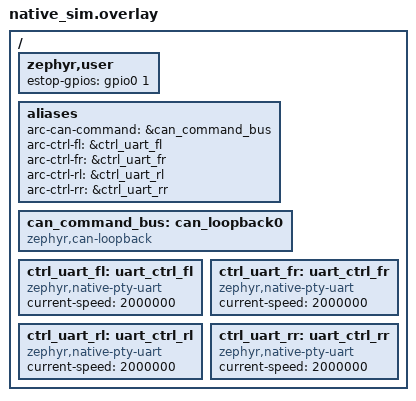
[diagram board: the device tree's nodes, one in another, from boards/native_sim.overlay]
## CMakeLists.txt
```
# Sync MCU firmware (ADR-0017). Build for any target from the repo root:
#   west build -b native_sim     firmware/sync-mcu/app -d firmware/sync-mcu/build/native_sim
#   west build -b nucleo_h723zg  firmware/sync-mcu/app -d firmware/sync-mcu/build/nucleo_h723zg
#   west build -b arc_sync       firmware/sync-mcu/app -d firmware/sync-mcu/build/arc_sync
# or `npx nx build sync-mcu` for all three (ADR-0028).

cmake_minimum_required(VERSION 3.20.0)

# Our own board definitions (boards/arc/arc_sync)
list(APPEND BOARD_ROOT ${CMAKE_CURRENT_LIST_DIR}/..)

find_package(Zephyr REQUIRED HINTS $ENV{ZEPHYR_BASE})
project(arc_sync_mcu)

# Generated from the ICDs (tools/gen-interfaces.sh): sync-link messages
# (systems/icd/sync-link.xml, ADR-0031) and command-bus frames
# (systems/icd/can-command.dbc)
target_include_directories(app PRIVATE generated/arc_mavlink generated/can_command)

target_sources(app PRIVATE
  src/main.c
  src/time_base.c
  src/sensors.c
  src/can_buses.c
  src/can_command_core.c
  generated/can_command/can_command.c
  src/controller_link_core.c
  src/controller_links.c
  src/safety.c
  src/fault_latch.c
  src/estop_input.c
  src/rate_monitor.c
  src/safety_task.c
  src/sync_link.c
)

target_sources_ifdef(CONFIG_ARC_SIM_CAN_BRIDGE app PRIVATE src/sim_can_bridge.c)
target_sources_ifdef(CONFIG_ARC_SIM_ESTOP app PRIVATE src/sim_estop.c)
```

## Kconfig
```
mainmenu "ARC sync MCU"

config ARC_HEARTBEAT_TIMEOUT_MS
	int "Operator heartbeat timeout (ms)"
	default 150
	help
	  Time without an operator heartbeat before the car starts braking
	  (SYS-04: rolls <= 2 m first; ~150 ms is ~1.4 m at 9 m/s; TBC).

config ARC_CAR_MAX_SPEED_MMPS
	int "The car's top speed (mm/s)"
	default 9000
	help
	  The cap for raising the safety envelope's speed limit (SYS-22):
	  SYS-01's 9 m/s. Moves to the car's configuration (ADR-0051).

config ARC_CAR_MAX_ACCEL_MMPS2
	int "The car's maximum acceleration (mm/s^2)"
	default 5000
	help
	  The cap for raising the envelope's acceleration limit (SYS-22).
	  TBD until measured; until then it equals the 5 m/s^2 default
	  (ADR-0052), so the limit can't be raised. Moves to the car's
	  configuration (ADR-0051).

config ARC_CAR_MAX_STEER_MRAD
	int "The car's steering range at the wheels, each side (mrad)"
	default 436
	help
	  About +/-25 degrees (ADR-0019; TBC). The default envelope allows
	  all of it (ADR-0052). Moves to the car's configuration (ADR-0051).

config ARC_COMMAND_TIMEOUT_MS
	int "Orin commands: age after which a command is dropped (ms)"
	default 150
	help
	  With no fresh ARC_DRIVE_COMMAND the output is a zero command (no
	  braking ramp). What the car should do when commands stop while the
	  heartbeat goes on is ICD-sync-link open issue 7; 150 ms follows
	  SYS-04's timeout and is TBC.

config ARC_COMMAND_RATE_HZ
	int "Orin commands: expected arrival rate (Hz)"
	default 500
	help
	  The rate the Orin bridge sends ARC_DRIVE_COMMAND at (ICD-sync-link,
	  TBC). ADR-0011 gives 200-500 Hz for motor commands; 500 Hz is the
	  command-bus budget (budgets/bus-load.csv). Only used to report a
	  stream that is off rate; it never stops the car.

config ARC_COMMAND_RATE_TOLERANCE_PCT
	int "Orin commands: how far off ARC_COMMAND_RATE_HZ is reported (%)"
	default 20
	help
	  TBC, nobody has chosen it. The rate is measured over one second.

config ARC_CAN_BRAKE_CURRENT_MA
	int "Command bus: brake current sent to all four controllers on a stop (mA)"
	default 0
	help
	  TBD: no value in the spec. 0 sends nothing on a stop, and the
	  controllers brake on their own command timeout (ADR-0035), later than
	  SYS-25's 20 ms. Needs the controllers' brake ramp (ADR-0012) settled.

config ARC_CAN_ERPM_PER_MPS
	int "Command bus: electrical rpm per m/s of commanded speed"
	default 0
	help
	  TBD: depends on the wheel diameter, gear ratio and pole pairs, which
	  are still changing (ADR-0026, ADR-0034, ADR-0040). 0 sends 0 A, so the
	  car can't drive until it is set.

config ARC_ESTOP_CUT_MS
	int "Reset: how long the e-stop must be held (ms)"
	default 2400
	help
	  T, the motor-bus cut after an e-stop press (ADR-0034, TBC 2.4 s).
	  A press released sooner doesn't reset a stop (ADR-0039).

config ARC_RESET_CHECK_WINDOW_MS
	int "Reset: how long the power-on checks may take after release (ms)"
	default 3000
	help
	  The controllers restart after the cut and must report again, with
	  no state bits or faults and every wheel stopped, within this time;
	  otherwise the car stays latched (ADR-0039; 3 s set 2026-10-25, TBC).

config ARC_RESET_MAX_STOPS
	int "Reset: stops since power-on that need a restart"
	default 3
	help
	  ADR-0039 item 5 (TBC). Corners reporting the e-stop don't count.

config ARC_WHEEL_STOPPED_ERPM
	int "Reset: the largest |eRPM| that counts as a stopped wheel"
	default 100
	help
	  For the power-on checks' "all wheels stopped" (ADR-0039): an
	  allowance for the speed estimate's noise at standstill
	  (set 2026-10-25, TBC until measured).

config ARC_SIM_ESTOP
	bool "Simulation: the e-stop button over UDP"
	depends on BOARD_NATIVE_SIM && NET_SOCKETS && GPIO_EMUL
	help
	  The emulated e-stop input, set by a simulator over UDP (sim_estop.c).
	  Never on the car.

config ARC_SIM_ESTOP_PORT
	int "Simulation: UDP port for the e-stop button"
	default 52102
	depends on ARC_SIM_ESTOP

config ARC_SIM_CAN_BRIDGE
	bool "Simulation: carry the command bus over UDP"
	depends on BOARD_NATIVE_SIM && NET_SOCKETS
	help
	  The command-bus loopback device, bridged to a simulator over UDP
	  (sim_can_bridge.c). Never on the car.

config ARC_SIM_CAN_PORT_RX
	int "Simulation: UDP port for frames from the simulator"
	default 52100
	depends on ARC_SIM_CAN_BRIDGE

config ARC_SIM_CAN_PORT_TX
	int "Simulation: UDP port for frames to the simulator"
	default 52101
	depends on ARC_SIM_CAN_BRIDGE

config ARC_CONTROLLER_SILENCE_MS
	int "Controller links: silence that stops the car (ms)"
	default 5
	help
	  A motor controller that sends no valid ARC_MOTOR_STATUS for longer
	  than this stops all four corners (SYS-25, ADR-0035; 5 ms is TBC).
	  A host running native_sim in real time with fake controllers can't
	  keep a 5 ms cadence (the scheduler jitters by more); the
	  firmware-in-the-loop run raises it, the unit tests keep the real value.

config ARC_SYNC_LINK_PORT_RX
	int "Sync link: UDP port the sync MCU listens on"
	default 52000
	help
	  ICD-sync-link. The Orin's car backend sends here.

config ARC_SYNC_LINK_PORT_TX
	int "Sync link: UDP port the Orin listens on"
	default 52001
	help
	  ICD-sync-link.

config ARC_SYNC_LINK_PEER
	string "Sync link: the Orin's IPv4 address"
	default "192.168.70.1"
	help
	  The Orin's wired address on the car's internal network
	  (ICD-network, set 2026-10-25, #72). boards/native_sim.conf sets 127.0.0.1 for the
	  firmware and the bridge on one machine.

source "Kconfig.zephyr"
```

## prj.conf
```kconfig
# Common to every target. Target-specific settings live in boards/<board>.conf.
CONFIG_LOG=y
CONFIG_ASSERT=y
```

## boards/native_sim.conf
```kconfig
# native_sim: the sync link runs over the host's own sockets (Zephyr's
# offloaded sockets), so the full stack runs on a laptop (ADR-0028)
CONFIG_NETWORKING=y
CONFIG_NET_IPV4=y
CONFIG_NET_IPV6=n
CONFIG_NET_UDP=y
CONFIG_NET_DRIVERS=y
CONFIG_NET_SOCKETS=y
CONFIG_NET_SOCKETS_OFFLOAD=y
CONFIG_NET_NATIVE_OFFLOADED_SOCKETS=y
CONFIG_ETH_NATIVE_TAP=n
# the bridge runs on this machine too
CONFIG_ARC_SYNC_LINK_PEER="127.0.0.1"
# the controller UARTs (boards/native_sim.overlay), interrupt-driven as on the MCU
CONFIG_SERIAL=y
CONFIG_UART_INTERRUPT_DRIVEN=y
# 1 kHz traffic needs a tick finer than the default 10 ms: a 1 ms sleep would last 10 to 20
CONFIG_SYS_CLOCK_TICKS_PER_SEC=10000
# the command bus: a loopback CAN device, bridged to the simulator over UDP
CONFIG_CAN=y
CONFIG_CAN_LOOPBACK=y
CONFIG_ARC_SIM_CAN_BRIDGE=y
# the e-stop status input: an emulated GPIO the simulator drives over UDP
CONFIG_GPIO=y
CONFIG_ARC_SIM_ESTOP=y
# Placeholders for simulation only; the car's values are TBD (see app/Kconfig):
# 10 A of brake current, and the fake controllers' model (62 mm wheels, 13.5:1, 2 pole pairs)
CONFIG_ARC_CAN_BRAKE_CURRENT_MA=10000
CONFIG_ARC_CAN_ERPM_PER_MPS=8317
```

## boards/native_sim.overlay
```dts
/*
 * native_sim: the four motor-controller UARTs (ICD-controller-telemetry,
 * ADR-0034) as pseudo-terminals. Each prints its /dev/pts path at start-up;
 * tools/sim attaches a fake controller to it. The console stays on stdout.
 */
/ {
	/* the e-stop status input (estop_input.c): an emulated pin, pressed by the
	 * simulator through sim_estop.c; 0 at start-up, released */
	zephyr,user {
		estop-gpios = <&gpio0 1 GPIO_ACTIVE_HIGH>;
	};

	aliases {
		arc-can-command = &can_command_bus;
		arc-ctrl-fl = &ctrl_uart_fl;
		arc-ctrl-fr = &ctrl_uart_fr;
		arc-ctrl-rl = &ctrl_uart_rl;
		arc-ctrl-rr = &ctrl_uart_rr;
	};

	/* the command bus (ADR-0009): a loopback device; sim_can_bridge.c carries it over UDP */
	can_command_bus: can_loopback0 {
		status = "okay";
		compatible = "zephyr,can-loopback";
	};

	ctrl_uart_fl: uart_ctrl_fl {
		status = "okay";
		compatible = "zephyr,native-pty-uart";
		current-speed = <2000000>;
	};

	ctrl_uart_fr: uart_ctrl_fr {
		status = "okay";
		compatible = "zephyr,native-pty-uart";
		current-speed = <2000000>;
	};

	ctrl_uart_rl: uart_ctrl_rl {
		status = "okay";
		compatible = "zephyr,native-pty-uart";
		current-speed = <2000000>;
	};

	ctrl_uart_rr: uart_ctrl_rr {
		status = "okay";
		compatible = "zephyr,native-pty-uart";
		current-speed = <2000000>;
	};
};
```

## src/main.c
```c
/*
 * Sync MCU firmware (ADR-0017): the car's time base, sensors, CAN buses,
 * motor-controller telemetry links, safety envelope and heartbeat watchdog,
 * and the link to the Orin.
 * Architecture: systems/software/architecture.md.
 */

#include <zephyr/kernel.h>
#include <zephyr/logging/log.h>

#include "can_buses.h"
#include "controller_links.h"
#include "safety_task.h"
#ifdef CONFIG_ARC_SIM_CAN_BRIDGE
#include "sim_can_bridge.h"
#endif
#ifdef CONFIG_ARC_SIM_ESTOP
#include "sim_estop.h"
#endif
#include "sensors.h"
#include "sync_link.h"
#include "time_base.h"

LOG_MODULE_REGISTER(main, LOG_LEVEL_INF);

int main(void)
{
	LOG_INF("ARC sync MCU starting on %s", CONFIG_BOARD);

	time_base_init();
	sensors_init();
	safety_task_init(); /* before anything that reads its decision */
	can_buses_init();
	controller_links_init();
	sync_link_init();
#ifdef CONFIG_ARC_SIM_CAN_BRIDGE
	sim_can_bridge_init();
#endif
#ifdef CONFIG_ARC_SIM_ESTOP
	sim_estop_init();
#endif

	while (true) {
		/* everything runs in threads: the controller links, the sync link, the safety task */
		k_sleep(K_SECONDS(1));
	}

	return 0;
}
```

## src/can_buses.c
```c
#include <zephyr/drivers/can.h>
#include <zephyr/kernel.h>
#include <zephyr/logging/log.h>

#include "can_buses.h"

LOG_MODULE_REGISTER(can_buses, LOG_LEVEL_INF);

#if DT_NODE_EXISTS(DT_ALIAS(arc_can_command))

#include "can_command_core.h"
#include "safety_task.h"
#include "time_base.h"

#define COMMAND_BITRATE 1000000 /* ADR-0009: 1 Mbit/s */
#define TX_PERIOD_MS 2          /* 500 Hz (bus-load.csv, TBC) */

static const struct device *const can = DEVICE_DT_GET(DT_ALIAS(arc_can_command));
static const struct cc_config config = {
	.erpm_per_mps = CONFIG_ARC_CAN_ERPM_PER_MPS,
	.brake_current_a = CONFIG_ARC_CAN_BRAKE_CURRENT_MA / 1000.0f,
};

static atomic_t status_count[CC_CORNERS];
static int64_t status_last_ns[CC_CORNERS];

const struct device *can_buses_command_device(void)
{
	return can;
}

uint32_t can_buses_status_count(int corner)
{
	return corner >= 0 && corner < CC_CORNERS ? (uint32_t)atomic_get(&status_count[corner]) : 0;
}

int64_t can_buses_status_last_ns(int corner)
{
	return corner >= 0 && corner < CC_CORNERS ? status_last_ns[corner] : 0;
}

static void on_status(const struct device *dev, struct can_frame *frame, void *user_data)
{
	ARG_UNUSED(dev);
	ARG_UNUSED(user_data);

	int corner = cc_status_1_corner(frame->id);

	if (corner >= 0) {
		status_last_ns[corner] = time_base_now_ns();
		atomic_inc(&status_count[corner]);
	}
}

static void tx_thread(void *a, void *b, void *c)
{
	ARG_UNUSED(a);
	ARG_UNUSED(b);
	ARG_UNUSED(c);

	enum cc_kind last_kind = (enum cc_kind)-1;
	uint32_t errors = 0;

	while (true) {
		struct safety_output decision = safety_task_output();
		struct cc_plan plan = cc_make_plan(&config, &decision);

		if (plan.kind != last_kind) {
			LOG_INF("command bus: sending %s", cc_kind_name(plan.kind));
			if (plan.kind == CC_NONE) {
				LOG_ERR("braking, but ARC_CAN_BRAKE_CURRENT_MA is not set: the "
					"controllers brake on their own timeout (150 ms), not "
					"within SYS-25's 20 ms");
			}
			last_kind = plan.kind;
		}
		if (plan.kind != CC_NONE) {
			for (int i = 0; i < CC_CORNERS; i++) {
				struct can_frame f = {.id = plan.frame[i].id, .flags = CAN_FRAME_IDE,
						      .dlc = plan.frame[i].len};

				memcpy(f.data, plan.frame[i].data, plan.frame[i].len);
				int err = can_send(can, &f, K_NO_WAIT, NULL, NULL);

				if (err && (errors++ % 1000) == 0) {
					LOG_WRN("command bus: send failed (%d), %u so far", err,
						errors);
				}
			}
		}
		k_sleep(K_MSEC(TX_PERIOD_MS));
	}
}

K_THREAD_STACK_DEFINE(can_tx_stack, 2048);
static struct k_thread tx_data;

int can_buses_init(void)
{
	if (!device_is_ready(can)) {
		LOG_ERR("command bus device not ready");
		return -ENODEV;
	}
	int err = can_set_bitrate(can, COMMAND_BITRATE);

	if (err && err != -ENOTSUP) {
		LOG_ERR("command bus bitrate: %d", err);
		return err;
	}
#if DT_NODE_HAS_COMPAT(DT_ALIAS(arc_can_command), zephyr_can_loopback)
	/* the loopback device hands a sent frame to the receive filters only in this mode:
	 * that is how sim_can_bridge.c sees what the firmware sends */
	err = can_set_mode(can, CAN_MODE_LOOPBACK);
	if (err) {
		LOG_ERR("command bus mode: %d", err);
		return err;
	}
#endif
	err = can_start(can);
	if (err) {
		LOG_ERR("command bus start: %d", err);
		return err;
	}
	for (int i = 0; i < CC_CORNERS; i++) {
		struct can_filter filter = {.id = cc_status_1_id(i), .mask = CAN_EXT_ID_MASK,
					    .flags = CAN_FILTER_IDE};

		if (can_add_rx_filter(can, on_status, NULL, &filter) < 0) {
			LOG_ERR("command bus: no filter for STATUS_1 of corner %d", i);
			return -ENOSPC;
		}
	}
	k_thread_create(&tx_data, can_tx_stack, K_THREAD_STACK_SIZEOF(can_tx_stack), tx_thread, NULL, NULL,
			NULL, K_PRIO_PREEMPT(4), 0, K_NO_WAIT);
	k_thread_name_set(&tx_data, "can_tx");
	LOG_INF("command bus up: %d bit/s, every %d ms to the four controllers", COMMAND_BITRATE,
		TX_PERIOD_MS);
	return 0;
}

#else

const struct device *can_buses_command_device(void)
{
	return NULL;
}

uint32_t can_buses_status_count(int corner)
{
	ARG_UNUSED(corner);
	return 0;
}

int64_t can_buses_status_last_ns(int corner)
{
	ARG_UNUSED(corner);
	return 0;
}

int can_buses_init(void)
{
	LOG_INF("not implemented yet");
	return 0;
}

#endif
```

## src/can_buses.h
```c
/*
 * The CAN buses: classic command bus to the four motor controllers
 * (ADR-0009) and the CAN-FD steering bus to the moteus-c1 (ADR-0019).
 * Command frame layouts come from can-command.dbc.
 *
 * The command bus sends every 2 ms, to all four controllers: the safety
 * decision as frames (can_command_core), never silent, so the controllers'
 * own command timeout trips only on real loss (ADR-0035). It receives
 * STATUS_1 from each controller. The steering bus is a stub.
 *
 * Only native_sim has the command-bus device so far (a loopback device, with
 * the simulator bridge behind it: sim_can_bridge.c); the other boards build a
 * stub until their CAN controllers are in the board files.
 * A safety function: changes need their own tests and a second reviewer.
 */

#ifndef ARC_CAN_BUSES_H
#define ARC_CAN_BUSES_H

#include <stdint.h>

#include <zephyr/device.h>

int can_buses_init(void);

/* The command bus device, or NULL where there isn't one. */
const struct device *can_buses_command_device(void);

/* STATUS_1 frames received from a corner, and the sync-MCU time of the last (0 if none). */
uint32_t can_buses_status_count(int corner);
int64_t can_buses_status_last_ns(int corner);

#endif /* ARC_CAN_BUSES_H */
```

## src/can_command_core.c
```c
#include <math.h>
#include <string.h>

#include "can_command.h"
#include "can_command_core.h"

#define ERPM_LIMIT 200000.0f /* can-command.dbc range */
#define BRAKE_LIMIT_A 200.0f

/* One function per frame kind and corner: the generated code names them per corner. */
#define KIND_FUNCS(KIND, kind, field)                                                    \
	static void kind##_frame(int c, double v, struct cc_frame *f)                         \
	{                                                                                     \
		switch (c) {                                                                  \
		case 0: {                                                                     \
			struct can_command_##kind##_fl_t m = {.field = can_command_##kind##_fl_##field##_encode(v)}; \
			f->len = can_command_##kind##_fl_pack(f->data, &m, 8);               \
			f->id = CAN_COMMAND_##KIND##_FL_FRAME_ID;                             \
			break; }                                                              \
		case 1: {                                                                     \
			struct can_command_##kind##_fr_t m = {.field = can_command_##kind##_fr_##field##_encode(v)}; \
			f->len = can_command_##kind##_fr_pack(f->data, &m, 8);               \
			f->id = CAN_COMMAND_##KIND##_FR_FRAME_ID;                             \
			break; }                                                              \
		case 2: {                                                                     \
			struct can_command_##kind##_rl_t m = {.field = can_command_##kind##_rl_##field##_encode(v)}; \
			f->len = can_command_##kind##_rl_pack(f->data, &m, 8);               \
			f->id = CAN_COMMAND_##KIND##_RL_FRAME_ID;                             \
			break; }                                                              \
		default: {                                                                    \
			struct can_command_##kind##_rr_t m = {.field = can_command_##kind##_rr_##field##_encode(v)}; \
			f->len = can_command_##kind##_rr_pack(f->data, &m, 8);               \
			f->id = CAN_COMMAND_##KIND##_RR_FRAME_ID;                             \
			break; }                                                              \
		}                                                                             \
	}

KIND_FUNCS(SET_CURRENT, set_current, current)
KIND_FUNCS(SET_CURRENT_BRAKE, set_current_brake, current_brake)
KIND_FUNCS(SET_RPM, set_rpm, erpm)

static float limit(float v, float lo, float hi)
{
	return v < lo ? lo : v > hi ? hi : v;
}

struct cc_plan cc_make_plan(const struct cc_config *cfg, const struct safety_output *out)
{
	struct cc_plan plan = {0};

	if (out->brake) {
		if (!(cfg->brake_current_a > 0.0f)) {
			plan.kind = CC_NONE;
			return plan;
		}
		plan.kind = CC_BRAKE;
		for (int c = 0; c < CC_CORNERS; c++) {
			set_current_brake_frame(c, limit(cfg->brake_current_a, 0.0f, BRAKE_LIMIT_A),
						&plan.frame[c]);
		}
		return plan;
	}

	if (out->reason == SAFETY_DRIVING && cfg->erpm_per_mps > 0.0f) {
		plan.kind = CC_RPM;
		float erpm = limit(out->cmd.speed_mps * cfg->erpm_per_mps, -ERPM_LIMIT, ERPM_LIMIT);

		for (int c = 0; c < CC_CORNERS; c++) {
			set_rpm_frame(c, erpm, &plan.frame[c]);
		}
		return plan;
	}

	plan.kind = CC_ZERO_CURRENT;
	for (int c = 0; c < CC_CORNERS; c++) {
		set_current_frame(c, 0.0, &plan.frame[c]);
	}
	return plan;
}

uint32_t cc_status_1_id(int corner)
{
	static const uint32_t id[CC_CORNERS] = {
		CAN_COMMAND_STATUS_1_FL_FRAME_ID, CAN_COMMAND_STATUS_1_FR_FRAME_ID,
		CAN_COMMAND_STATUS_1_RL_FRAME_ID, CAN_COMMAND_STATUS_1_RR_FRAME_ID,
	};

	return corner >= 0 && corner < CC_CORNERS ? id[corner] : 0;
}

int cc_status_1_corner(uint32_t id)
{
	for (int c = 0; c < CC_CORNERS; c++) {
		if (id == cc_status_1_id(c)) {
			return c;
		}
	}
	return -1;
}

const char *cc_kind_name(enum cc_kind k)
{
	switch (k) {
	case CC_NONE:
		return "nothing (no brake current configured)";
	case CC_ZERO_CURRENT:
		return "zero current";
	case CC_RPM:
		return "rpm";
	case CC_BRAKE:
		return "brake";
	}
	return "?";
}
```

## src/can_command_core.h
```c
/*
 * What goes on the command bus (ICD can-command, ADR-0009, ADR-0035), with no
 * I/O: from the safety decision, the four frames for the four controllers.
 *
 *   brake            SET_CURRENT_BRAKE to all four, at the configured current;
 *                    with none configured, nothing is sent and the controllers
 *                    brake on their own command timeout (ADR-0035): slower than
 *                    SYS-25's 20 ms
 *   driving          SET_RPM from the speed, at the configured eRPM per m/s;
 *                    with none configured it is 0 rpm
 *   anything else    SET_CURRENT 0 A: the bus is never silent while drive is
 *                    enabled, so the controllers' timeout trips only on real loss
 *
 * The brake current and the eRPM per m/s have no value in the spec (TBD).
 * A safety function: changes need their own tests and a second reviewer.
 */

#ifndef ARC_CAN_COMMAND_CORE_H
#define ARC_CAN_COMMAND_CORE_H

#include <stdbool.h>
#include <stdint.h>

#include "safety.h"

#define CC_CORNERS 4

struct cc_config {
	float erpm_per_mps;  /* 0: not configured */
	float brake_current_a; /* 0: not configured */
};

struct cc_frame {
	uint32_t id; /* 29-bit extended ID */
	uint8_t len;
	uint8_t data[8];
};

enum cc_kind {
	CC_NONE = 0,      /* braking, but no brake current configured: send nothing */
	CC_ZERO_CURRENT,  /* SET_CURRENT 0 A */
	CC_RPM,           /* SET_RPM */
	CC_BRAKE          /* SET_CURRENT_BRAKE */
};

struct cc_plan {
	enum cc_kind kind;
	struct cc_frame frame[CC_CORNERS]; /* FL, FR, RL, RR; valid unless kind is CC_NONE */
};

struct cc_plan cc_make_plan(const struct cc_config *cfg, const struct safety_output *out);

/* The STATUS_1 ID of a corner (extended), and whether an ID is one of them. */
uint32_t cc_status_1_id(int corner);
/* Corner 0..3 if id is a STATUS_1 frame from a controller, else -1. */
int cc_status_1_corner(uint32_t id);

const char *cc_kind_name(enum cc_kind k);

#endif /* ARC_CAN_COMMAND_CORE_H */
```

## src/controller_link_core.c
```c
#include <string.h>

#include "controller_link_core.h"

void cl_init(struct cl_links *l, int64_t silence_ns, uint16_t version)
{
	memset(l, 0, sizeof(*l));
	l->silence_ns = silence_ns;
	l->version = version;
}

static void count_sequence(struct cl_corner *c, uint8_t seq)
{
	if (c->seq_known) {
		c->gaps += (uint8_t)(seq - c->last_seq - 1);
	}
	c->seq_known = true;
	c->last_seq = seq;
	c->frames++;
}

static void handle(struct cl_links *l, int corner, const mavlink_message_t *m, int64_t now_ns)
{
	struct cl_corner *c = &l->c[corner];

	switch (m->msgid) {
	case MAVLINK_MSG_ID_ARC_MOTOR_STATUS: {
		mavlink_arc_motor_status_t s;

		mavlink_msg_arc_motor_status_decode(m, &s);
		if (s.corner != corner) {
			/* a miswired or crossed UART: not this corner's data */
			c->bad++;
			return;
		}
		count_sequence(c, m->seq);
		c->seen = true;
		c->last_valid_ns = now_ns;
		c->fault = s.fault;
		c->state = s.state;
		c->erpm = s.erpm;
		break;
	}
	case MAVLINK_MSG_ID_ARC_LINK_STATUS: {
		mavlink_arc_link_status_t s;

		mavlink_msg_arc_link_status_decode(m, &s);
		count_sequence(c, m->seq);
		c->version_known = true;
		c->peer_version = s.protocol_version;
		break;
	}
	default:
		c->bad++; /* not a message this link carries */
		break;
	}
}

void cl_feed(struct cl_links *l, int corner, const uint8_t *buf, size_t len, int64_t now_ns)
{
	if (corner < 0 || corner >= CL_CORNERS) {
		return;
	}

	struct cl_corner *c = &l->c[corner];

	for (size_t i = 0; i < len; i++) {
		mavlink_message_t out;
		mavlink_status_t out_status;
		uint8_t r = mavlink_frame_char_buffer(&c->msg, &c->status, buf[i], &out, &out_status);

		if (r == MAVLINK_FRAMING_OK) {
			handle(l, corner, &out, now_ns);
		} else if (r != MAVLINK_FRAMING_INCOMPLETE) {
			c->bad++; /* bad CRC or bad signature */
		}
	}
}

static enum cl_reason stop_reason(const struct cl_links *l, const struct cl_corner *c,
				  int64_t now_ns)
{
	if (!c->seen) {
		return CL_OK; /* not ready is judged separately */
	}
	if (c->state & ARC_MOTOR_STATE_ESTOP) {
		return CL_ESTOP;
	}
	if (c->state & ARC_MOTOR_STATE_COMMAND_TIMEOUT) {
		return CL_COMMAND_TIMEOUT;
	}
	if (c->state != 0) {
		/* ICD-controller-telemetry: any state bit stops the car. A bit this
		 * firmware doesn't know (a newer controller) must not be ignored. */
		return CL_UNKNOWN_STATE;
	}
	if (c->fault != 0) {
		return CL_FAULT;
	}
	if (now_ns - c->last_valid_ns > l->silence_ns) {
		return CL_SILENT;
	}
	return CL_OK;
}

enum cl_reason cl_check(const struct cl_links *l, int64_t now_ns, int *corner)
{
	for (int i = 0; i < CL_CORNERS; i++) {
		enum cl_reason r = stop_reason(l, &l->c[i], now_ns);

		if (r != CL_OK) {
			if (corner) {
				*corner = i;
			}
			return r;
		}
	}
	for (int i = 0; i < CL_CORNERS; i++) {
		if (l->c[i].version_known && l->c[i].peer_version != l->version) {
			if (corner) {
				*corner = i;
			}
			return CL_VERSION;
		}
	}
	for (int i = 0; i < CL_CORNERS; i++) {
		if (!l->c[i].seen) {
			if (corner) {
				*corner = i;
			}
			return CL_NOT_READY;
		}
	}
	return CL_OK;
}

bool cl_all_stopped(const struct cl_links *l, int32_t max_erpm)
{
	for (int i = 0; i < CL_CORNERS; i++) {
		const struct cl_corner *c = &l->c[i];

		if (!c->seen || c->erpm > max_erpm || c->erpm < -max_erpm) {
			return false;
		}
	}
	return true;
}

bool cl_is_stop(enum cl_reason r)
{
	return r == CL_SILENT || r == CL_FAULT || r == CL_ESTOP || r == CL_COMMAND_TIMEOUT ||
	       r == CL_UNKNOWN_STATE;
}

const char *cl_reason_name(enum cl_reason r)
{
	switch (r) {
	case CL_OK:
		return "ok";
	case CL_NOT_READY:
		return "not ready";
	case CL_VERSION:
		return "protocol version mismatch";
	case CL_SILENT:
		return "silent";
	case CL_FAULT:
		return "fault";
	case CL_ESTOP:
		return "e-stop";
	case CL_COMMAND_TIMEOUT:
		return "command timeout";
	case CL_UNKNOWN_STATE:
		return "unknown state bits";
	}
	return "?";
}
```

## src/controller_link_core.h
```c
/*
 * The decision logic of the motor-controller links (ICD-controller-telemetry,
 * SYS-25, ADR-0035), with no I/O: it takes bytes and a time and answers.
 * That keeps it testable anywhere, in virtual time, with the exact sequences
 * that matter (a corner silent for 5 ms, a frame with a bad CRC).
 *
 * A safety function: changes need their own tests and a second reviewer.
 */

#ifndef ARC_CONTROLLER_LINK_CORE_H
#define ARC_CONTROLLER_LINK_CORE_H

#include <stdbool.h>
#include <stddef.h>
#include <stdint.h>

#include "arc_sync_link/mavlink.h"

#define CL_CORNERS 4 /* FL, FR, RL, RR: ARC_CORNER 0..3 */

/* Why the car should stop, or not yet drive. */
enum cl_reason {
	CL_OK = 0,
	CL_NOT_READY,      /* a corner hasn't reported yet: drive is refused, no stop */
	CL_VERSION,        /* a controller's protocol version differs: drive is refused */
	CL_SILENT,         /* no valid ARC_MOTOR_STATUS within the window (SYS-25) */
	CL_FAULT,          /* the controller reports a non-zero fault code */
	CL_ESTOP,          /* the controller is braking on its e-stop input */
	CL_COMMAND_TIMEOUT, /* the controller is braking for lack of commands */
	CL_UNKNOWN_STATE    /* a state bit this firmware doesn't know: ICD says any bit stops */
};

struct cl_corner {
	mavlink_message_t msg; /* parser state */
	mavlink_status_t status;
	bool seen;
	int64_t last_valid_ns; /* sync-MCU time the last valid status completed */
	uint8_t fault;
	uint8_t state; /* ARC_MOTOR_STATE bitmask */
	int32_t erpm;  /* electrical speed, from the last valid status */
	bool version_known;
	uint16_t peer_version;
	bool seq_known;
	uint8_t last_seq;
	uint32_t frames; /* valid frames of any message */
	uint32_t gaps;   /* frames missing, from the sequence numbers */
	uint32_t bad;    /* frames rejected: CRC, unknown message, wrong corner */
};

struct cl_links {
	struct cl_corner c[CL_CORNERS];
	int64_t silence_ns; /* longest a corner may go without a valid status */
	uint16_t version;   /* the protocol version this firmware was built from */
};

void cl_init(struct cl_links *l, int64_t silence_ns, uint16_t version);

/* Bytes read from a corner's UART at now_ns (sync-MCU time). */
void cl_feed(struct cl_links *l, int corner, const uint8_t *buf, size_t len, int64_t now_ns);

/*
 * The condition at now_ns. For a stop reason (CL_SILENT, CL_FAULT, CL_ESTOP,
 * CL_COMMAND_TIMEOUT) *corner is the first corner affected, lowest first.
 * A corner is silent when more than silence_ns has passed since its last
 * valid ARC_MOTOR_STATUS. A corner that has never reported isn't silent, it
 * isn't ready: that is CL_NOT_READY, which refuses drive without stopping.
 */
enum cl_reason cl_check(const struct cl_links *l, int64_t now_ns, int *corner);

/* Every corner has reported and its last |eRPM| is at most max_erpm: the
 * wheels are stopped (ADR-0039's power-on checks). Freshness is cl_check's. */
bool cl_all_stopped(const struct cl_links *l, int32_t max_erpm);

const char *cl_reason_name(enum cl_reason r);
bool cl_is_stop(enum cl_reason r);

#endif /* ARC_CONTROLLER_LINK_CORE_H */
```

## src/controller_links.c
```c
#include <zephyr/device.h>
#include <zephyr/drivers/uart.h>
#include <zephyr/kernel.h>
#include <zephyr/logging/log.h>
#include <zephyr/spinlock.h>
#include <zephyr/sys/ring_buffer.h>

#include "controller_links.h"
#include "time_base.h"

LOG_MODULE_REGISTER(controller_links, LOG_LEVEL_INF);

static struct k_spinlock lock;
static enum cl_reason latched = CL_OK;
static int latched_corner = -1;
static enum cl_reason current = CL_NOT_READY;
static int current_corner = -1;
static uint8_t current_fault;
static bool wheels_stopped;

/* K_SPINLOCK must be left by falling out of its block: a return inside skips the unlock */
enum cl_reason controller_links_stop(int *corner)
{
	enum cl_reason r = CL_OK;
	int c = -1;

	K_SPINLOCK(&lock) {
		r = latched;
		c = latched_corner;
	}
	if (corner) {
		*corner = c;
	}
	return r;
}

enum cl_reason controller_links_state(int *corner)
{
	enum cl_reason r = CL_NOT_READY;
	int c = -1;

	K_SPINLOCK(&lock) {
		r = current;
		c = current_corner;
	}
	if (corner) {
		*corner = c;
	}
	return r;
}

void controller_links_reset_inputs(enum cl_reason *reason, int *corner, uint8_t *fault_code,
				   bool *stopped)
{
	K_SPINLOCK(&lock) {
		*reason = current;
		*corner = current_corner;
		*fault_code = current_fault;
		*stopped = wheels_stopped;
	}
}

void controller_links_reset(void)
{
	K_SPINLOCK(&lock) {
		latched = CL_OK;
		latched_corner = -1;
	}
	LOG_INF("any-corner stop reset");
}

#if DT_NODE_EXISTS(DT_ALIAS(arc_ctrl_fl)) && DT_NODE_EXISTS(DT_ALIAS(arc_ctrl_fr)) && \
	DT_NODE_EXISTS(DT_ALIAS(arc_ctrl_rl)) && DT_NODE_EXISTS(DT_ALIAS(arc_ctrl_rr))

static const char *const corner_name[CL_CORNERS] = {"FL", "FR", "RL", "RR"};

#define CTRL_UART(n) DEVICE_DT_GET(DT_ALIAS(arc_ctrl_##n))

static const struct device *const uart[CL_CORNERS] = {
	CTRL_UART(fl), CTRL_UART(fr), CTRL_UART(rl), CTRL_UART(rr),
};

#define RX_BYTES 1024 /* about 18 ms of one controller's traffic */

static uint8_t rx_mem[CL_CORNERS][RX_BYTES];
static struct ring_buf rx[CL_CORNERS];
static uint32_t overruns[CL_CORNERS];
static uint32_t overruns_reported[CL_CORNERS];
/* When each corner's newest bytes arrived (set in the interrupt): a frame is
 * as old as its arrival, not as old as the thread's turn to read it */
static int64_t arrived_ns[CL_CORNERS];
static K_SEM_DEFINE(rx_sem, 0, 1);
static struct cl_links links;

/* The receive interrupt only moves bytes; the thread below decides. */
static void uart_isr(const struct device *dev, void *user_data)
{
	int i = (int)(intptr_t)user_data;
	uint8_t buf[64];

	while (uart_irq_update(dev) && uart_irq_is_pending(dev)) {
		if (!uart_irq_rx_ready(dev)) {
			break;
		}
		int n = uart_fifo_read(dev, buf, sizeof(buf));

		if (n <= 0) {
			break;
		}
		if (ring_buf_put(&rx[i], buf, n) < (uint32_t)n) {
			overruns[i]++;
		}
		arrived_ns[i] = time_base_now_ns();
	}
	k_sem_give(&rx_sem);
}

static void update(int64_t now)
{
	int corner = -1;
	enum cl_reason r = cl_check(&links, now, &corner);
	bool first_stop = false;
	bool changed = false;

	bool stopped = cl_all_stopped(&links, CONFIG_ARC_WHEEL_STOPPED_ERPM);
	uint8_t fault = corner >= 0 ? links.c[corner].fault : 0;

	K_SPINLOCK(&lock) {
		changed = (r != current || corner != current_corner);
		current = r;
		current_corner = corner;
		current_fault = fault;
		wheels_stopped = stopped;
		if (cl_is_stop(r) && latched == CL_OK) {
			latched = r;
			latched_corner = corner;
			first_stop = true;
		}
	}
	if (first_stop) {
		LOG_ERR("any-corner stop: %s %s", corner_name[corner], cl_reason_name(r));
	} else if (changed && !cl_is_stop(r)) {
		LOG_INF("controller links: %s%s%s", cl_reason_name(r), corner >= 0 ? " at " : "",
			corner >= 0 ? corner_name[corner] : "");
	}
}

static void links_thread(void *a, void *b, void *c)
{
	ARG_UNUSED(a);
	ARG_UNUSED(b);
	ARG_UNUSED(c);

	uint8_t buf[128];

	while (true) {
		k_sem_take(&rx_sem, K_MSEC(1)); /* wake at least every ms to judge silence */

		for (int i = 0; i < CL_CORNERS; i++) {
			/* the arrival time first, then the bytes: anything that landed in
			 * between is stamped slightly early, never late */
			unsigned int key = irq_lock();
			int64_t arrived = arrived_ns[i];

			irq_unlock(key);

			uint32_t n;

			while ((n = ring_buf_get(&rx[i], buf, sizeof(buf))) > 0) {
				cl_feed(&links, i, buf, n, arrived);
			}
			if (overruns[i] != overruns_reported[i]) {
				LOG_WRN("controller %s: receive buffer overran (%u so far)",
					corner_name[i], overruns[i]);
				overruns_reported[i] = overruns[i];
			}
		}
		update(time_base_now_ns());
	}
}

/* The detection path of SYS-25: ahead of everything but the interrupts */
K_THREAD_STACK_DEFINE(links_stack, 4096);
static struct k_thread links_thread_data;

int controller_links_init(void)
{
	cl_init(&links, (int64_t)CONFIG_ARC_CONTROLLER_SILENCE_MS * 1000000, MAVLINK_VERSION);

	for (int i = 0; i < CL_CORNERS; i++) {
		if (!device_is_ready(uart[i])) {
			LOG_ERR("controller UART %s not ready", corner_name[i]);
			return -ENODEV;
		}
		ring_buf_init(&rx[i], sizeof(rx_mem[i]), rx_mem[i]);
		uart_irq_callback_user_data_set(uart[i], uart_isr, (void *)(intptr_t)i);
		uart_irq_rx_enable(uart[i]);
	}
	k_thread_create(&links_thread_data, links_stack, K_THREAD_STACK_SIZEOF(links_stack),
			links_thread, NULL, NULL, NULL, K_PRIO_PREEMPT(2), 0, K_NO_WAIT);
	k_thread_name_set(&links_thread_data, "controller_links");
	LOG_INF("controller links up, stop after %d ms of silence", CONFIG_ARC_CONTROLLER_SILENCE_MS);
	return 0;
}

#else

int controller_links_init(void)
{
	LOG_INF("no controller UARTs on this board yet");
	return 0;
}

#endif
```

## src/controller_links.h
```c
/*
 * Telemetry from the four motor controllers: one UART each, point to
 * point, full status at 1 kHz stamped at sampling (ADR-0024, ADR-0034).
 * Message set: ICD-controller-telemetry: MAVLink 2, ARC_MOTOR_STATUS
 * from systems/icd/sync-link.xml. Stub.
 */

#ifndef ARC_CONTROLLER_LINKS_H
#define ARC_CONTROLLER_LINKS_H

int controller_links_init(void);

#endif /* ARC_CONTROLLER_LINKS_H */
```

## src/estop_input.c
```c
#include <zephyr/devicetree.h>
#include <zephyr/drivers/gpio.h>
#include <zephyr/logging/log.h>

#include "estop_input.h"

LOG_MODULE_REGISTER(estop_input, LOG_LEVEL_INF);

#if DT_NODE_HAS_PROP(DT_PATH(zephyr_user), estop_gpios)

static const struct gpio_dt_spec pin = GPIO_DT_SPEC_GET(DT_PATH(zephyr_user), estop_gpios);
static bool ready;

int estop_input_init(void)
{
	if (!gpio_is_ready_dt(&pin) || gpio_pin_configure_dt(&pin, GPIO_INPUT) < 0) {
		LOG_ERR("e-stop input not ready: reads as pressed");
		return -ENODEV;
	}
	ready = true;
	return 0;
}

bool estop_input_pressed(void)
{
	/* anything but a clean "released" is pressed */
	return !ready || gpio_pin_get_dt(&pin) != 0;
}

#else

int estop_input_init(void)
{
	LOG_WRN("no e-stop input on this board (#95): reads as pressed, so the car can't be reset");
	return 0;
}

bool estop_input_pressed(void)
{
	return true;
}

#endif
```

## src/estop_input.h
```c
/*
 * The e-stop status input (E-32 through the power section's stop circuit,
 * ICD-power-sync-stack ESTOP_STATUS): whether the button on the car is
 * pressed. The pin, level and polarity are TBD (#95); devicetree gives the
 * pin as the zephyr,user property estop-gpios, active when pressed.
 *
 * Fail-safe: a board without the property reads as pressed, so the car can't
 * be reset there (fault_latch.h). On native_sim it is an emulated pin that
 * the simulator drives (sim_estop.c).
 */

#ifndef ARC_ESTOP_INPUT_H
#define ARC_ESTOP_INPUT_H

#include <stdbool.h>

int estop_input_init(void);
bool estop_input_pressed(void);

#endif /* ARC_ESTOP_INPUT_H */
```

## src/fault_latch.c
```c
#include "fault_latch.h"

void fl_init(struct fault_latch *fl, const struct fl_config *cfg, int64_t now_ms)
{
	*fl = (struct fault_latch){
		.cfg = *cfg,
		.state = FL_LATCHED,
		.cause = FL_CAUSE_BOOT, /* ADR-0039: it boots latched */
		.corner_reason = CL_OK,
		.corner = -1,
		.since_ms = now_ms,
	};
}

static void enter(struct fault_latch *fl, enum fl_state s, int64_t now_ms)
{
	fl->state = s;
	fl->since_ms = now_ms;
}

/* A cause that only a restart and an inspection clear, or FL_CAUSE_NONE. */
static enum fl_cause restart_cause(const struct fl_inputs *in)
{
	if (in->corners == CL_FAULT && in->fault_code == FL_VESC_FAULT_ABS_OVER_CURRENT) {
		return FL_CAUSE_OVERCURRENT;
	}
	if (in->corners == CL_FAULT && in->fault_code == FL_VESC_FAULT_OVER_VOLTAGE) {
		return FL_CAUSE_OVERVOLTAGE;
	}
	return FL_CAUSE_NONE;
}

static enum fl_event stop(struct fault_latch *fl, int64_t now_ms, const struct fl_inputs *in)
{
	enum fl_cause restart = restart_cause(in);

	fl->corner_reason = in->corners;
	fl->corner = in->corner;
	/* a corner reporting the e-stop isn't a fault: the button was pressed,
	 * or its wiring is checked at the reset */
	if (in->corners != CL_ESTOP) {
		fl->stops++;
	}
	if (restart == FL_CAUSE_NONE && fl->stops >= fl->cfg.max_stops) {
		restart = FL_CAUSE_TOO_MANY;
	}
	if (restart != FL_CAUSE_NONE) {
		fl->cause = restart;
		enter(fl, FL_RESTART, now_ms);
		return FL_EV_RESTART;
	}
	fl->cause = FL_CAUSE_CORNER;
	enter(fl, FL_LATCHED, now_ms);
	return FL_EV_LATCHED;
}

static enum fl_event checks_failed(struct fault_latch *fl, int64_t now_ms,
				   const struct fl_inputs *in)
{
	enum fl_cause restart = restart_cause(in);

	fl->corner_reason = in->corners;
	fl->corner = in->corner;
	fl->wheels_moving = !in->wheels_stopped;
	if (in->corners == CL_ESTOP) {
		restart = FL_CAUSE_ESTOP_WIRING; /* ADR-0035: the button is released */
	}
	if (restart != FL_CAUSE_NONE) {
		fl->cause = restart;
		enter(fl, FL_RESTART, now_ms);
		return FL_EV_RESTART;
	}
	fl->cause = FL_CAUSE_CHECKS;
	enter(fl, FL_LATCHED, now_ms);
	return FL_EV_CHECKS_FAILED;
}

enum fl_event fl_update(struct fault_latch *fl, int64_t now_ms, const struct fl_inputs *in)
{
	switch (fl->state) {
	case FL_CLEAR:
		if (in->estop_pressed) {
			fl->cause = FL_CAUSE_ESTOP;
			fl->corner_reason = CL_OK;
			fl->corner = -1;
			enter(fl, FL_LATCHED, now_ms);
			return FL_EV_LATCHED;
		}
		if (cl_is_stop(in->corners)) {
			return stop(fl, now_ms, in);
		}
		return FL_EV_NONE;

	case FL_LATCHED:
		if (in->estop_pressed) {
			enter(fl, FL_PRESSED, now_ms);
			return FL_EV_PRESSED;
		}
		return FL_EV_NONE;

	case FL_PRESSED:
		if (in->estop_pressed) {
			return FL_EV_NONE;
		}
		if (now_ms - fl->since_ms >= fl->cfg.cut_ms) {
			enter(fl, FL_CHECKING, now_ms);
			return FL_EV_CHECKING;
		}
		enter(fl, FL_LATCHED, now_ms);
		return FL_EV_RELEASED_EARLY;

	case FL_CHECKING:
		if (in->estop_pressed) {
			enter(fl, FL_PRESSED, now_ms);
			return FL_EV_PRESSED;
		}
		if (in->corners == CL_OK && in->wheels_stopped) {
			fl->cause = FL_CAUSE_NONE;
			fl->corner_reason = CL_OK;
			fl->corner = -1;
			enter(fl, FL_CLEAR, now_ms);
			return FL_EV_CLEARED;
		}
		if (now_ms - fl->since_ms >= fl->cfg.check_window_ms) {
			return checks_failed(fl, now_ms, in);
		}
		return FL_EV_NONE;

	case FL_RESTART:
		return FL_EV_NONE;
	}
	return FL_EV_NONE;
}

bool fl_clear(const struct fault_latch *fl)
{
	return fl->state == FL_CLEAR;
}

bool fl_brake(const struct fault_latch *fl)
{
	/* Not while checking: the car stopped before the press, and the controllers
	 * coming back must see a live bus, not a brake that may not be configured */
	switch (fl->state) {
	case FL_LATCHED:
	case FL_PRESSED:
		return fl->cause != FL_CAUSE_BOOT;
	case FL_RESTART:
		return true;
	case FL_CHECKING:
	case FL_CLEAR:
		return false;
	}
	return true;
}

const char *fl_state_name(enum fl_state s)
{
	switch (s) {
	case FL_LATCHED:
		return "latched";
	case FL_PRESSED:
		return "e-stop held";
	case FL_CHECKING:
		return "power-on checks";
	case FL_CLEAR:
		return "reset";
	case FL_RESTART:
		return "restart required";
	}
	return "?";
}

const char *fl_cause_name(enum fl_cause c)
{
	switch (c) {
	case FL_CAUSE_NONE:
		return "none";
	case FL_CAUSE_BOOT:
		return "power-on";
	case FL_CAUSE_ESTOP:
		return "e-stop pressed";
	case FL_CAUSE_CORNER:
		return "corner stop";
	case FL_CAUSE_CHECKS:
		return "power-on checks failed";
	case FL_CAUSE_TOO_MANY:
		return "too many stops since power-on";
	case FL_CAUSE_OVERCURRENT:
		return "controller over-current";
	case FL_CAUSE_OVERVOLTAGE:
		return "controller over-voltage";
	case FL_CAUSE_ESTOP_WIRING:
		return "e-stop wiring fault";
	}
	return "?";
}

const char *fl_event_name(enum fl_event e)
{
	switch (e) {
	case FL_EV_NONE:
		return "none";
	case FL_EV_LATCHED:
		return "latched";
	case FL_EV_PRESSED:
		return "e-stop pressed";
	case FL_EV_RELEASED_EARLY:
		return "e-stop released before the motor-bus cut";
	case FL_EV_CHECKING:
		return "e-stop released: power-on checks";
	case FL_EV_CLEARED:
		return "power-on checks passed: re-arm to drive";
	case FL_EV_CHECKS_FAILED:
		return "power-on checks failed";
	case FL_EV_RESTART:
		return "restart required";
	}
	return "?";
}
```

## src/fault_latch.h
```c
/*
 * The fault-stop latch and its reset (SYS-25, ADR-0039). Pure logic: times
 * and inputs are passed in, so the tests run it in virtual time. The Zephyr
 * side is safety_task.c.
 *
 * A stop latches and the car stays stopped. It boots latched, so a power
 * cycle can't skip the reset. The reset: press the e-stop button on the car,
 * hold it at least until the motor-bus cut at T, release it, and the
 * power-on checks pass within the check window: every corner reporting with
 * no state bits or faults, every wheel stopped. Then the operator re-arms
 * (safety.h). Some causes need a full restart and an inspection instead.
 *
 * Not checked yet: the steering (no steering driver; ADR-0038). Decided
 * 2026-10-25 to skip it everywhere until the driver exists.
 *
 * A safety function: changes need their own tests and a second reviewer.
 */

#ifndef ARC_FAULT_LATCH_H
#define ARC_FAULT_LATCH_H

#include <stdbool.h>
#include <stdint.h>

#include "controller_link_core.h"

struct fl_config {
	int64_t cut_ms;          /* T: the motor-bus cut after a press (ADR-0034, TBC 2.4 s) */
	int64_t check_window_ms; /* how long the power-on checks may take after release (TBC 3 s) */
	int max_stops;           /* this many stops since power-on need a restart (TBC 3) */
};

enum fl_state {
	FL_LATCHED,  /* stopped: waiting for the e-stop button */
	FL_PRESSED,  /* the button is held: waiting for T */
	FL_CHECKING, /* released after T: the power-on checks */
	FL_CLEAR,    /* reset: the car may drive once the operator re-arms */
	FL_RESTART,  /* only a power cycle and an inspection clear this (ADR-0039 item 5) */
};

enum fl_cause {
	FL_CAUSE_NONE = 0,
	FL_CAUSE_BOOT,         /* power-on */
	FL_CAUSE_ESTOP,        /* the e-stop button was pressed */
	FL_CAUSE_CORNER,       /* a SYS-25 stop: see corner_reason, corner */
	FL_CAUSE_CHECKS,       /* the power-on checks failed: see corner_reason, corner, wheels */
	FL_CAUSE_TOO_MANY,     /* max_stops reached */
	FL_CAUSE_OVERCURRENT,  /* a controller reported over-current */
	FL_CAUSE_OVERVOLTAGE,  /* a controller reported over-voltage */
	FL_CAUSE_ESTOP_WIRING, /* a corner reports e-stop with the button released */
};

/* What the latch looks at, every tick. */
struct fl_inputs {
	bool estop_pressed;      /* the sync MCU's e-stop status input */
	enum cl_reason corners;  /* cl_check() now */
	int corner;              /* the corner it names, or -1 */
	uint8_t fault_code;      /* that corner's VESC fault code, when corners is CL_FAULT */
	bool wheels_stopped;     /* every corner reporting |eRPM| at or below the threshold */
};

struct fault_latch {
	struct fl_config cfg;
	enum fl_state state;
	enum fl_cause cause;
	enum cl_reason corner_reason; /* for FL_CAUSE_CORNER and FL_CAUSE_CHECKS */
	int corner;
	bool wheels_moving;           /* for FL_CAUSE_CHECKS */
	int stops;                    /* SYS-25 stops since power-on */
	int64_t since_ms;             /* when the current state began */
};

/* What changed in this update, for the log. */
enum fl_event {
	FL_EV_NONE = 0,
	FL_EV_LATCHED,         /* a stop: state LATCHED (or RESTART), cause set */
	FL_EV_PRESSED,         /* the button went down */
	FL_EV_RELEASED_EARLY,  /* released before T: still latched */
	FL_EV_CHECKING,        /* released after T: checks started */
	FL_EV_CLEARED,         /* the checks passed */
	FL_EV_CHECKS_FAILED,   /* the window ran out: latched again, cause CHECKS */
	FL_EV_RESTART,         /* a cause that needs a restart */
};

/* VESC fault codes that need a restart (mc_fault_code in the VESC firmware's datatypes.h) */
#define FL_VESC_FAULT_OVER_VOLTAGE 1
#define FL_VESC_FAULT_ABS_OVER_CURRENT 4

void fl_init(struct fault_latch *fl, const struct fl_config *cfg, int64_t now_ms);

enum fl_event fl_update(struct fault_latch *fl, int64_t now_ms, const struct fl_inputs *in);

/* Reset and not stopped since: drive is allowed once the operator re-arms. */
bool fl_clear(const struct fault_latch *fl);

/* The car must brake: stopped for anything but power-on. */
bool fl_brake(const struct fault_latch *fl);

const char *fl_state_name(enum fl_state s);
const char *fl_cause_name(enum fl_cause c);
const char *fl_event_name(enum fl_event e);

#endif /* ARC_FAULT_LATCH_H */
```
